AUTOSAR XML (schema 4-2-2)
package /AUTOSAR_StbM/SwComponentTypes
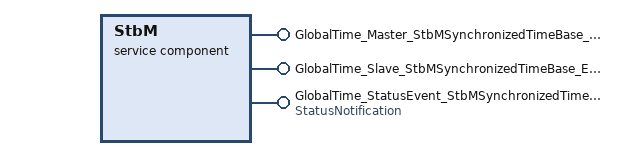
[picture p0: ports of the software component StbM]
  service sw component type StbM
    provide port GlobalTime_Master_StbMSynchronizedTimeBase_Eth: provided-interface=GlobalTime_Master_StbMSynchronizedTimeBase_Eth
      provided-com-specs:
        operation=SetGlobalTime, queue-length=1
        operation=UpdateGlobalTime, queue-length=1
        operation=GetMasterConfig, queue-length=1
        operation=SetUserData, queue-length=1
        operation=TriggerTimeTransmission, queue-length=1
    provide port GlobalTime_Slave_StbMSynchronizedTimeBase_Eth: provided-interface=GlobalTime_Slave_StbMSynchronizedTimeBase_Eth
      provided-com-specs:
        operation=GetRateDeviation, queue-length=1
        operation=GetCurrentTime, queue-length=1
        operation=GetTimeBaseStatus, queue-length=1
        operation=GetTimeLeap, queue-length=1
    provide port GlobalTime_StatusEvent_StbMSynchronizedTimeBase_Eth: nonqueued-sender-com-spec=eventNotification, provided-interface=StatusNotification
    behavior IB_StbM: handle-termination-and-restart=CAN-BE-TERMINATED-AND-RESTARTED
      8 x operation invoked event:
        OIE_GetCurrentTime_StbMSynchronizedTimeBase_Eth: start-on-event=GetCurrentTime, operation=GlobalTime_Slave_StbMSynchronizedTimeBase_Eth.GetCurrentTime
        OIE_GetTimeBaseStatus_StbMSynchronizedTimeBase_Eth: start-on-event=GetTimeBaseStatus, operation=GlobalTime_Slave_StbMSynchronizedTimeBase_Eth.GetTimeBaseStatus
        OIE_GetTimeLeap_StbMSynchronizedTimeBase_Eth: start-on-event=GetTimeLeap, operation=GlobalTime_Slave_StbMSynchronizedTimeBase_Eth.GetTimeLeap
        OIE_SetGlobalTime_StbMSynchronizedTimeBase_Eth: start-on-event=SetGlobalTime, operation=GlobalTime_Master_StbMSynchronizedTimeBase_Eth.SetGlobalTime
        OIE_UpdateGlobalTime_StbMSynchronizedTimeBase_Eth: start-on-event=UpdateGlobalTime, operation=GlobalTime_Master_StbMSynchronizedTimeBase_Eth.UpdateGlobalTime
        OIE_SetUserData_StbMSynchronizedTimeBase_Eth: start-on-event=SetUserData, operation=GlobalTime_Master_StbMSynchronizedTimeBase_Eth.SetUserData
        OIE_GetMasterConfig_StbMSynchronizedTimeBase_Eth: start-on-event=GetMasterConfig, operation=GlobalTime_Master_StbMSynchronizedTimeBase_Eth.GetMasterConfig
        OIE_TriggerTimeTransmission_StbMSynchronizedTimeBase_Eth: start-on-event=TriggerTimeTransmission, operation=GlobalTime_Master_StbMSynchronizedTimeBase_Eth.TriggerTimeTransmission
      port-api-options:
        {enable-take-address=false, indirect-api=false, port-defined-argument-value{value=0, value-type=StbM_SynchronizedTimeBaseType}, port=GlobalTime_Slave_StbMSynchronizedTimeBase_Eth}
        {enable-take-address=false, indirect-api=false, port-defined-argument-value{value=0, value-type=StbM_SynchronizedTimeBaseType}, port=GlobalTime_Master_StbMSynchronizedTimeBase_Eth}
        enable-take-address=true, indirect-api=false, port=GlobalTime_StatusEvent_StbMSynchronizedTimeBase_Eth
      10 x runnable, all with can-be-invoked-concurrently=true:
        SetGlobalTime: arguments=[symbol=timeBaseId, symbol=timeStamp, symbol=userData], symbol=StbM_SetGlobalTime
        UpdateGlobalTime: arguments=[symbol=timeBaseId, symbol=timeStamp, symbol=userData], symbol=StbM_UpdateGlobalTime
        GetMasterConfig: arguments=[symbol=timeBaseId, symbol=masterConfig], symbol=StbM_GetMasterConfig
        SetUserData: arguments=[symbol=timeBaseId, symbol=userData], symbol=StbM_SetUserData
        TriggerTimeTransmission: runnable-entity-argument=symbol=timeBaseId, symbol=StbM_TriggerTimeTransmission
        GetCurrentTime: arguments=[symbol=timeBaseId, symbol=timeStamp, symbol=userData], symbol=StbM_GetCurrentTime
        GetTimeBaseStatus: arguments=[symbol=timeBaseId, symbol=syncTimeBaseStatus, symbol=offsetTimeBaseStatus], symbol=StbM_GetTimeBaseStatus
        GetTimeLeap: arguments=[symbol=timeBaseId, symbol=timeJump], symbol=StbM_GetTimeLeap
        StatusNotification_StbMSynchronizedTimeBase_Eth: runnable-entity-argument=symbol=eventNotification, symbol=StatusNotificationCallback_StbMSynchronizedTimeBase_Eth
          data-send-points:
            access DataSendPoints_eventNotification: accessed-variable=GlobalTime_StatusEvent_StbMSynchronizedTimeBase_Eth.eventNotification
        RE_StbM_MainFunction
package /AUTOSAR_StbM/PortInterfaces
  client server interface GlobalTime_Master_StbMSynchronizedTimeBase_Eth: is-service=true, service-kind=SYNC-BASE-TIME-MANAGER
    5 x operation, all with possible-error=[GlobalTime_Master_StbMSynchronizedTimeBase_Eth/E_NOT_OK, GlobalTime_Master_StbMSynchronizedTimeBase_Eth/E_OK]:
      SetGlobalTime
        arg timeStamp: type=StbM_TimeStampType, direction=IN
        arg userData: type=StbM_UserDataType, direction=IN
      UpdateGlobalTime
        arg timeStamp: type=StbM_TimeStampType, direction=IN
        arg userData: type=StbM_UserDataType, direction=IN
      GetMasterConfig
        arg masterConfig: type=StbM_MasterConfigType, direction=OUT
      SetUserData
        arg userData: type=StbM_UserDataType, direction=IN
      TriggerTimeTransmission
    error E_NOT_OK: error-code=1
    error E_OK: error-code=0
  client server interface GlobalTime_Slave_StbMSynchronizedTimeBase_Eth: is-service=true, service-kind=SYNC-BASE-TIME-MANAGER
    4 x operation, all with possible-error=[GlobalTime_Slave_StbMSynchronizedTimeBase_Eth/E_NOT_OK, GlobalTime_Slave_StbMSynchronizedTimeBase_Eth/E_OK]:
      GetCurrentTime
        arg timeStamp: type=StbM_TimeStampType, direction=OUT
        arg userData: type=StbM_UserDataType, direction=OUT
      GetTimeBaseStatus
        arg syncTimeBaseStatus: type=StbM_TimeBaseStatusType, direction=OUT
        arg offsetTimeBaseStatus: type=StbM_TimeBaseStatusType, direction=OUT
      GetTimeLeap
        arg timeJump: type=StbM_TimeDiffType, direction=OUT
      GetRateDeviation
        arg rateDeviation: type=StbM_RateDeviationType, direction=OUT
    error E_NOT_OK: error-code=1
    error E_OK: error-code=0
  sender receiver interface StatusNotification
    data eventNotification: type=StbM_TimeBaseNotificationType
package /AUTOSAR_StbM/ImplementationDataTypes
  14 x impl type:
    StbM_TimeBaseStatusType: compu {mask 0x01: 0=FALSE (TIMEOUT) (Bit 0 (LSB): 0x00: No Timeout on receiving Synchronisation Messages 0x01: Timeout on receiving Synchronisation Messages), mask 0x01: 1=TRUE (TIMEOUT) (Bit 0 (LSB): 0x00: No Timeout on receiving Synchronisation Messages 0x01: Timeout on receiving Synchronisation Messages), mask 0x02: 0=FALSE (StbM_Reserved) (Bit 1: Always 0 (reserved for future usage)), mask 0x02: 2=TRUE (StbM_Reserved) (Bit 1: Always 0 (reserved for future usage)), mask 0x04: 0=FALSE (SYNC_TO_GATEWAY) (Bit 2 0x00: Local Time Base is synchronous to Global Time Master 0x04: Local Time Base updates are based on a Time Gateway below the Global Time Master), mask 0x04: 4=TRUE (SYNC_TO_GATEWAY) (Bit 2 0x00: Local Time Base is synchronous to Global Time Master 0x04: Local Time Base updates are based on a Time Gateway below the Global Time Master), mask 0x08: 0=FALSE (GLOBAL_TIME_BASE) (Bit 3 0x00: Local Time Base is based on Local Time Base reference clock only (never synchronized with Global Time Base) 0x08: Local Time Base was at least synchronized with Global Time Base one time), mask 0x08: 8=TRUE (GLOBAL_TIME_BASE) (Bit 3 0x00: Local Time Base is based on Local Time Base reference clock only (never synchronized with Global Time Base) 0x08: Local Time Base was at least synchronized with Global Time Base one time), mask 0x10: 0=FALSE (TIMELEAP_FUTURE) (Bit 4 0x00: No leap into the future within the received time for Time Base 0x10: Leap into the future within the received time for Time Base exceeds a configured threshold), mask 0x10: 16=TRUE (TIMELEAP_FUTURE) (Bit 4 0x00: No leap into the future within the received time for Time Base 0x10: Leap into the future within the received time for Time Base exceeds a configured threshold), mask 0x20: 0=FALSE (TIMELEAP_PAST) (Bit 5 0x00: No leap into the past within the received time for Time Base 0x20: Leap into the past within the received time for Time Base exceeds a configured threshold), mask 0x20: 32=TRUE (TIMELEAP_PAST) (Bit 5 0x00: No leap into the past within the received time for Time Base 0x20: Leap into the past within the received time for Time Base exceeds a configured threshold)}, implementation-data-type=uint8
    StbM_TimeStampType: category=STRUCTURE
      4 x element, all with category=TYPE_REFERENCE:
        timeBaseStatus: implementation-data-type=StbM_TimeBaseStatusType
        nanoseconds: implementation-data-type=uint32
        seconds: implementation-data-type=uint32
        secondsHi: implementation-data-type=uint16
    StbM_TimeStampExtendedType: category=STRUCTURE
      element timeBaseStatus: implementation-data-type=StbM_TimeBaseStatusType
      element nanoseconds: implementation-data-type=uint32
      element seconds: implementation-data-type=uint64
    StbM_UserDataType: category=STRUCTURE
      4 x element, all with category=TYPE_REFERENCE, implementation-data-type=uint8:
        userDataLength
        userByte{0..2}
    StbM_SynchronizedTimeBaseType: implementation-data-type=uint16
    StbM_RateDeviationType: implementation-data-type=sint16
    StbM_TimeBaseNotificationType: compu {mask 0x01: 0=FALSE (EV_GLOBAL_TIME) (Bit 0 (LSB): 0: synchronization to global time master not changed 1: GLOBAL_TIME_BASE in StbM_TimeBaseStatusType has changed from 0 to 1), mask 0x01: 1=TRUE (EV_GLOBAL_TIME) (Bit 0 (LSB): 0: synchronization to global time master not changed 1: GLOBAL_TIME_BASE in StbM_TimeBaseStatusType has changed from 0 to 1), mask 0x01: 0=FALSE (EV_TIMEOUT_OCCURRED) (Bit 1: 1: TIMEOUT bit in timeBaseStatus has changed from 0 to 1 0: otherwise), mask 0x01: 1=TRUE (EV_TIMEOUT_OCCURRED) (Bit 1: 1: TIMEOUT bit in timeBaseStatus has changed from 0 to 1 0: otherwise), mask 0x04: 0=FALSE (EV_TIMEOUT_REMOVED) (Bit 2 1: TIMEOUT bit in timeBaseStatus has changed from 1 to 0 0: otherwise), mask 0x04: 4=TRUE (EV_TIMEOUT_REMOVED) (Bit 2 1: TIMEOUT bit in timeBaseStatus has changed from 1 to 0 0: otherwise), mask 0x08: 0=FALSE (EV_TIMELEAP_FUTURE) (Bit 3 1: TIMELEAP_FUTURE bit in timeBaseStatus has changed from 0 to 1 0: otherwise), mask 0x08: 8=TRUE (EV_TIMELEAP_FUTURE) (Bit 3 1: TIMELEAP_FUTURE bit in timeBaseStatus has changed from 0 to 1 0: otherwise), mask 0x10: 0=FALSE (EV_TIMELEAP_FUTURE_REMOVED) (Bit 4 1: TIMELEAP_FUTURE bit in timeBaseStatus has changed from 1 to 0 0: otherwise), mask 0x10: 16=TRUE (EV_TIMELEAP_FUTURE_REMOVED) (Bit 4 1: TIMELEAP_FUTURE bit in timeBaseStatus has changed from 1 to 0 0: otherwise), mask 0x20: 0=FALSE (EV_TIMELEAP_PAST) (Bit 5 1: TIMELEAP_PAST bit in timeBaseStatus has changed from 0 to 1 0: otherwise), mask 0x20: 32=TRUE (EV_TIMELEAP_PAST) (Bit 5 1: TIMELEAP_PAST bit in timeBaseStatus has changed from 0 to 1 0: otherwise), mask 0x40: 0=FALSE (EV_TIMELEAP_PAST_REMOVED) (Bit 6 1: TIMELEAP_PAST bit in timeBaseStatus has changed from 1 to 0 0: otherwise), mask 0x40: 64=TRUE (EV_TIMELEAP_PAST_REMOVED) (Bit 6 1: TIMELEAP_PAST bit in timeBaseStatus has changed from 1 to 0 0: otherwise), mask 0x80: 0=FALSE (EV_SYNC_TO_SUBDOMAIN) (Bit 7 1: SYNC_TO_GATEWAY bit in timeBaseStatus has changed from 0 to 1 0: otherwise), mask 0x80: 128=TRUE (EV_SYNC_TO_SUBDOMAIN) (Bit 7 1: SYNC_TO_GATEWAY bit in timeBaseStatus has changed from 0 to 1 0: otherwise), mask 0x100: 0=FALSE (EV_SYNC_TO_GLOBAL_MASTER) (Bit 8 1: SYNC_TO_GATEWAY bit of Time Domain changes from 1 to 0 0: otherwise), mask 0x100: 256=TRUE (EV_SYNC_TO_GLOBAL_MASTER) (Bit 8 1: SYNC_TO_GATEWAY bit of Time Domain changes from 1 to 0 0: otherwise), mask 0x0200: 0=FALSE (EV_RESYNC) (Bit 9: 1: A synchronization of the local time to the valid Global Time value has occured 0: No resynchronization event occured), mask 0x0200: 512=TRUE (EV_RESYNC) (Bit 9: 1: A synchronization of the local time to the valid Global Time value has occured 0: No resynchronization event occured), mask 0x0400: 0=FALSE (EV_RATECORRECTION) (Bit 10 1: a valid rate correction has been calculated (not beyond limits) 0: No rate correction calculated), mask 0x0400: 1024=TRUE (EV_RATECORRECTION) (Bit 10 1: a valid rate correction has been calculated (not beyond limits) 0: No rate correction calculated)}, implementation-data-type=uint32
    StbM_SyncRecordTableHeadType: category=STRUCTURE
      element SynchronizedTimeDomain: implementation-data-type=uint8
      element HWfrequency: implementation-data-type=uint32
      element HWprescaler: implementation-data-type=uint32
    StbM_SyncRecordTableBlockType: category=STRUCTURE
      8 x element, all with category=TYPE_REFERENCE:
        GlbSeconds: implementation-data-type=uint32
        GlbNanoSeconds: implementation-data-type=uint32
        VirtualLocalTimeLow: implementation-data-type=uint32
        LocSeconds: implementation-data-type=uint32
        LocNanoSeconds: implementation-data-type=uint32
        PathDelay: implementation-data-type=uint32
        RateDeviation: implementation-data-type=StbM_RateDeviationType
        TimeBaseStatus: implementation-data-type=StbM_TimeBaseStatusType
    StbM_OffsetRecordTableHeadType: category=STRUCTURE
      element OffsetTimeDomain: implementation-data-type=uint8
    StbM_OffsetRecordTableBlockType: category=STRUCTURE
      element GlbSeconds: implementation-data-type=uint32
      element GlbNanoSeconds: implementation-data-type=uint32
      element TimeBaseStatus: implementation-data-type=StbM_TimeBaseStatusType
    StbM_MasterConfigType: compu {0x00=STBM_SYSTEM_WIDE_MASTER_DISABLED, 0x01=STBM_SYSTEM_WIDE_MASTER_ENABLED}, implementation-data-type=uint8
    StbM_TimeDiffType: implementation-data-type=sint32
    StbM_CustomerIdType: implementation-data-type=uint16
package /AUTOSAR_StbM/SwcImplementations
  swc implementation SWCIMPL_StbM: programming-language=C, sw-version=1.0.0, swc-bsw-mapping=SwcBswMapping_StbM, behavior=IB_StbM
    code-descriptors:
      code Code: artifact-descriptors=autosar-engineering-object={short-label=ArEngObj, category=SWSRC}
package /AUTOSAR_StbM/AUTOSAR_StbM/SwcBswMappings
  swc bsw mapping SwcBswMapping_StbM: bsw-behavior=IB_StbM, swc-bsw-runnable-mapping{bsw-entity=SE_MainFunction, swc-runnable=RE_StbM_MainFunction}, swc-behavior=IB_StbM
